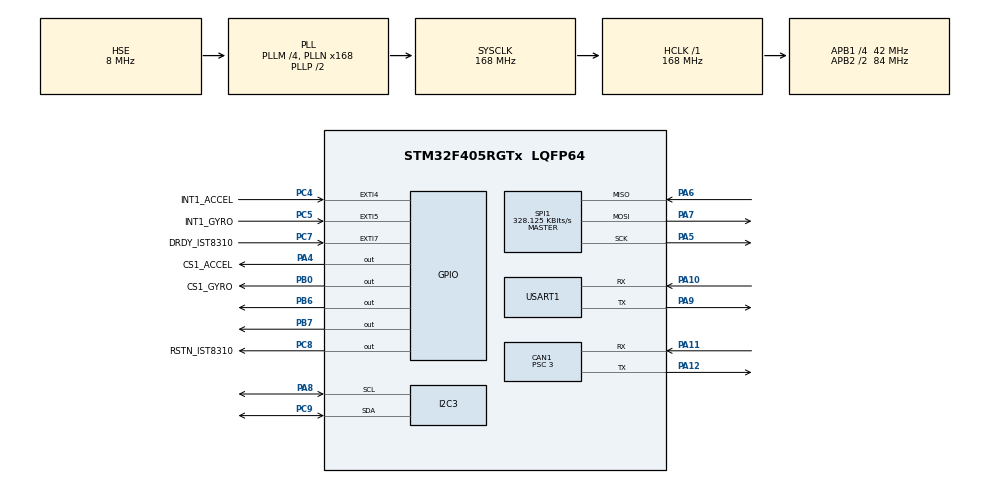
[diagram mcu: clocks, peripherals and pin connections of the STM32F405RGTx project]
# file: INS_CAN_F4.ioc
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CAN1.BS1=CAN_BS1_10TQ
CAN1.BS2=CAN_BS2_3TQ
CAN1.CalculateBaudRate=1000000
CAN1.CalculateTimeBit=1000
CAN1.CalculateTimeQuantum=71.42857142857143
CAN1.Prescaler=3
Dma.Request0=USART1_TX
Dma.Request1=SPI1_RX
Dma.Request2=SPI1_TX
Dma.SPI1_RX.1.Direction=DMA_PERIPH_TO_MEMORY
Dma.SPI1_RX.1.FIFOMode=DMA_FIFOMODE_DISABLE
Dma.SPI1_RX.1.Instance=DMA2_Stream2
Dma.SPI1_RX.1.MemDataAlignment=DMA_MDATAALIGN_BYTE
Dma.SPI1_RX.1.MemInc=DMA_MINC_ENABLE
Dma.SPI1_RX.1.Mode=DMA_NORMAL
Dma.SPI1_RX.1.PeriphDataAlignment=DMA_PDATAALIGN_BYTE
Dma.SPI1_RX.1.PeriphInc=DMA_PINC_DISABLE
Dma.SPI1_RX.1.Priority=DMA_PRIORITY_VERY_HIGH
Dma.SPI1_TX.2.Direction=DMA_MEMORY_TO_PERIPH
Dma.SPI1_TX.2.FIFOMode=DMA_FIFOMODE_DISABLE
Dma.SPI1_TX.2.Instance=DMA2_Stream3
Dma.SPI1_TX.2.MemDataAlignment=DMA_MDATAALIGN_BYTE
Dma.SPI1_TX.2.MemInc=DMA_MINC_ENABLE
Dma.SPI1_TX.2.Mode=DMA_NORMAL
Dma.SPI1_TX.2.PeriphDataAlignment=DMA_PDATAALIGN_BYTE
Dma.SPI1_TX.2.PeriphInc=DMA_PINC_DISABLE
Dma.SPI1_TX.2.Priority=DMA_PRIORITY_HIGH
Dma.USART1_TX.0.Direction=DMA_MEMORY_TO_PERIPH
Dma.USART1_TX.0.FIFOMode=DMA_FIFOMODE_DISABLE
Dma.USART1_TX.0.Instance=DMA2_Stream7
Dma.USART1_TX.0.MemDataAlignment=DMA_MDATAALIGN_BYTE
Dma.USART1_TX.0.MemInc=DMA_MINC_ENABLE
Dma.USART1_TX.0.Mode=DMA_NORMAL
Dma.USART1_TX.0.PeriphDataAlignment=DMA_PDATAALIGN_BYTE
Dma.USART1_TX.0.PeriphInc=DMA_PINC_DISABLE
Dma.USART1_TX.0.Priority=DMA_PRIORITY_VERY_HIGH
FREERTOS.INCLUDE_eTaskGetState=1
FREERTOS.INCLUDE_pcTaskGetTaskName=1
FREERTOS.INCLUDE_uxTaskGetStackHighWaterMark=1
FREERTOS.INCLUDE_vTaskCleanUpResources=1
FREERTOS.INCLUDE_vTaskDelayUntil=1
FREERTOS.INCLUDE_xEventGroupSetBitFromISR=1
FREERTOS.INCLUDE_xQueueGetMutexHolder=1
FREERTOS.INCLUDE_xSemaphoreGetMutexHolder=1
FREERTOS.INCLUDE_xTaskAbortDelay=1
FREERTOS.INCLUDE_xTaskGetCurrentTaskHandle=1
FREERTOS.INCLUDE_xTaskGetHandle=1
FREERTOS.INCLUDE_xTimerPendFunctionCall=1
FREERTOS.Tasks01=defaultTask,0,128,StartDefaultTask,As weak,NULL,Dynamic,NULL,NULL;sendTask,-3,256,SendTask,As weak,NULL,Dynamic,NULL,NULL
FREERTOS.configTOTAL_HEAP_SIZE=24576
FREERTOS.configUSE_TIMERS=1
I2C3.I2C_Mode=I2C_Fast
Mcu.Family=STM32F4
Mcu.Name=STM32F405RGTx
Mcu.Package=LQFP64
NVIC.CAN1_RX0_IRQn=true\:5\:0\:true\:false\:true\:true\:true\:true\:true
NVIC.CAN1_RX1_IRQn=true\:5\:0\:true\:false\:true\:true\:true\:true\:true
NVIC.DMA2_Stream2_IRQn=true\:5\:0\:true\:false\:false\:true\:false\:true\:true
NVIC.DMA2_Stream3_IRQn=true\:5\:0\:true\:false\:false\:true\:false\:true\:true
NVIC.DMA2_Stream7_IRQn=true\:5\:0\:true\:false\:true\:true\:false\:true\:true
NVIC.EXTI4_IRQn=true\:5\:0\:true\:false\:true\:true\:true\:true\:true
NVIC.EXTI9_5_IRQn=true\:5\:0\:true\:false\:true\:true\:true\:true\:true
NVIC.PriorityGroup=NVIC_PRIORITYGROUP_4
NVIC.TIM2_IRQn=true\:3\:0\:true\:false\:true\:false\:false\:true\:true
NVIC.TimeBase=TIM2_IRQn
NVIC.TimeBaseIP=TIM2
NVIC.USART1_IRQn=true\:5\:0\:false\:false\:true\:true\:true\:true\:true
PA10.Mode=Asynchronous
PA10.Signal=USART1_RX
PA11.GPIO_PuPd=GPIO_NOPULL
PA11.Mode=CAN_Activate
PA11.Signal=CAN1_RX
PA12.Mode=CAN_Activate
PA12.Signal=CAN1_TX
PA13.Mode=Serial_Wire
PA13.Signal=SYS_JTMS-SWDIO
PA14.Mode=Serial_Wire
PA14.Signal=SYS_JTCK-SWCLK
PA4.GPIO_Label=CS1_ACCEL
PA4.GPIO_PuPd=GPIO_PULLUP
PA4.GPIO_Speed=GPIO_SPEED_FREQ_HIGH
PA4.PinState=GPIO_PIN_SET
PA4.Signal=GPIO_Output
PA5.GPIO_PuPd=GPIO_PULLUP
PA5.Mode=Full_Duplex_Master
PA5.Signal=SPI1_SCK
PA6.GPIO_PuPd=GPIO_PULLUP
PA6.Mode=Full_Duplex_Master
PA6.Signal=SPI1_MISO
PA7.GPIO_PuPd=GPIO_PULLUP
PA7.Mode=Full_Duplex_Master
PA7.Signal=SPI1_MOSI
PA8.GPIO_Pu=GPIO_PULLUP
PA8.Mode=I2C
PA8.Signal=I2C3_SCL
PA9.Mode=Asynchronous
PA9.Signal=USART1_TX
PB0.GPIO_Label=CS1_GYRO
PB0.GPIO_PuPd=GPIO_PULLUP
PB0.GPIO_Speed=GPIO_SPEED_FREQ_HIGH
PB0.PinState=GPIO_PIN_SET
PB0.Signal=GPIO_Output
PB6.GPIO_ModeDefaultOutputPP=GPIO_MODE_OUTPUT_PP
PB6.GPIO_PuPd=GPIO_PULLUP
PB6.GPIO_Speed=GPIO_SPEED_FREQ_VERY_HIGH
PB6.PinState=GPIO_PIN_SET
PB6.Signal=GPIO_Output
PB7.GPIO_ModeDefaultOutputPP=GPIO_MODE_OUTPUT_OD
PB7.GPIO_PuPd=GPIO_PULLUP
PB7.GPIO_Speed=GPIO_SPEED_FREQ_VERY_HIGH
PB7.PinState=GPIO_PIN_SET
PB7.Signal=GPIO_Output
PC4.GPIO_Label=INT1_ACCEL
PC4.GPIO_ModeDefaultEXTI=GPIO_MODE_IT_FALLING
PC4.GPIO_PuPd=GPIO_PULLUP
PC4.Signal=GPXTI4
PC5.GPIO_Label=INT1_GYRO
PC5.GPIO_ModeDefaultEXTI=GPIO_MODE_IT_FALLING
PC5.GPIO_PuPd=GPIO_PULLUP
PC5.Signal=GPXTI5
PC7.GPIO_Label=DRDY_IST8310
PC7.GPIO_ModeDefaultEXTI=GPIO_MODE_IT_FALLING
PC7.GPIO_PuPd=GPIO_PULLUP
PC7.Signal=GPXTI7
PC8.GPIO_Label=RSTN_IST8310
PC8.GPIO_PuPd=GPIO_PULLUP
PC8.GPIO_Speed=GPIO_SPEED_FREQ_MEDIUM
PC8.PinState=GPIO_PIN_SET
PC8.Signal=GPIO_Output
PC9.GPIO_Pu=GPIO_PULLUP
PC9.Mode=I2C
PC9.Signal=I2C3_SDA
PH0-OSC_IN.Mode=HSE-External-Oscillator
PH0-OSC_IN.Signal=RCC_OSC_IN
PH1-OSC_OUT.Mode=HSE-External-Oscillator
PH1-OSC_OUT.Signal=RCC_OSC_OUT
ProjectManager.HeapSize=0x2000
ProjectManager.StackSize=0x4000
ProjectManager.TargetToolchain=MDK-ARM V5
RCC.48MHZClocksFreq_Value=84000000
RCC.AHBFreq_Value=168000000
RCC.APB1CLKDivider=RCC_HCLK_DIV4
RCC.APB1Freq_Value=42000000
RCC.APB1TimFreq_Value=84000000
RCC.APB2CLKDivider=RCC_HCLK_DIV2
RCC.APB2Freq_Value=84000000
RCC.APB2TimFreq_Value=168000000
RCC.CortexFreq_Value=168000000
RCC.HCLKFreq_Value=168000000
RCC.HSE_VALUE=8000000
RCC.HSI_VALUE=16000000
RCC.LSE_VALUE=32768
RCC.PLLM=4
RCC.PLLN=168
RCC.PLLSourceVirtual=RCC_PLLSOURCE_HSE
RCC.SYSCLKFreq_VALUE=168000000
RCC.SYSCLKSource=RCC_SYSCLKSOURCE_PLLCLK
RCC.VCOOutputFreq_Value=336000000
SPI1.BaudRatePrescaler=SPI_BAUDRATEPRESCALER_256
SPI1.CLKPhase=SPI_PHASE_2EDGE
SPI1.CLKPolarity=SPI_POLARITY_HIGH
SPI1.CalculateBaudRate=328.125 KBits/s
SPI1.Direction=SPI_DIRECTION_2LINES
SPI1.Mode=SPI_MODE_MASTER
SPI1.VirtualType=VM_MASTER
USART1.VirtualMode=VM_ASYNC
VP_FREERTOS_VS_CMSIS_V1.Mode=CMSIS_V1
VP_SYS_VS_tim2.Mode=TIM2
board=custom

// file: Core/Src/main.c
/* USER CODE BEGIN Header */
/**
  ******************************************************************************
  * @file           : main.c
  * @brief          : Main program body
  ******************************************************************************
  * @attention
  *
  * Copyright (c) 2023 STMicroelectronics.
  * All rights reserved.
  *
  * This software is licensed under terms that can be found in the LICENSE file
  * in the root directory of this software component.
  * If no LICENSE file comes with this software, it is provided AS-IS.
  *
  ******************************************************************************
  */
/* USER CODE END Header */
#include "main.h"
#include "cmsis_os.h"
#include "can.h"
#include "dma.h"
#include "i2c.h"
#include "spi.h"
#include "usart.h"
#include "gpio.h"

void SystemClock_Config(void);
void MX_FREERTOS_Init(void);

int main(void)
{

  /* MCU Configuration--------------------------------------------------------*/

  /* Reset of all peripherals, Initializes the Flash interface and the Systick. */
  HAL_Init();

  /* Configure the system clock */
  SystemClock_Config();

  /* Initialize all configured peripherals */
  MX_GPIO_Init();
  MX_DMA_Init();
  MX_CAN1_Init();
  MX_I2C3_Init();
  MX_SPI1_Init();
  MX_USART1_UART_Init();

  /* Call init function for freertos objects (in freertos.c) */
  MX_FREERTOS_Init();

  /* Start scheduler */
  osKernelStart();
  /* We should never get here as control is now taken by the scheduler */
  /* Infinite loop */
  while (1)
  {

  }
}

void SystemClock_Config(void)
{
  RCC_OscInitTypeDef RCC_OscInitStruct = {0};
  RCC_ClkInitTypeDef RCC_ClkInitStruct = {0};

  /** Configure the main internal regulator output voltage
  */
  __HAL_RCC_PWR_CLK_ENABLE();
  __HAL_PWR_VOLTAGESCALING_CONFIG(PWR_REGULATOR_VOLTAGE_SCALE1);

  /** Initializes the RCC Oscillators according to the specified parameters
  * in the RCC_OscInitTypeDef structure.
  */
  RCC_OscInitStruct.OscillatorType = RCC_OSCILLATORTYPE_HSE;
  RCC_OscInitStruct.HSEState = RCC_HSE_ON;
  RCC_OscInitStruct.PLL.PLLState = RCC_PLL_ON;
  RCC_OscInitStruct.PLL.PLLSource = RCC_PLLSOURCE_HSE;
  RCC_OscInitStruct.PLL.PLLM = 4;
  RCC_OscInitStruct.PLL.PLLN = 168;
  RCC_OscInitStruct.PLL.PLLP = RCC_PLLP_DIV2;
  RCC_OscInitStruct.PLL.PLLQ = 4;
  if (HAL_RCC_OscConfig(&RCC_OscInitStruct) != HAL_OK)
  {
    Error_Handler();
  }

  /** Initializes the CPU, AHB and APB buses clocks
  */
  RCC_ClkInitStruct.ClockType = RCC_CLOCKTYPE_HCLK|RCC_CLOCKTYPE_SYSCLK
                              |RCC_CLOCKTYPE_PCLK1|RCC_CLOCKTYPE_PCLK2;
  RCC_ClkInitStruct.SYSCLKSource = RCC_SYSCLKSOURCE_PLLCLK;
  RCC_ClkInitStruct.AHBCLKDivider = RCC_SYSCLK_DIV1;
  RCC_ClkInitStruct.APB1CLKDivider = RCC_HCLK_DIV4;
  RCC_ClkInitStruct.APB2CLKDivider = RCC_HCLK_DIV2;

  if (HAL_RCC_ClockConfig(&RCC_ClkInitStruct, FLASH_LATENCY_5) != HAL_OK)
  {
    Error_Handler();
  }
}

void HAL_TIM_PeriodElapsedCallback(TIM_HandleTypeDef *htim)
{
  if (htim->Instance == TIM2) {
    HAL_IncTick();
  }
}

void Error_Handler(void)
{
  __disable_irq();
  while (1)
  {
  }
}

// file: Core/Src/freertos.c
/* USER CODE BEGIN Header */
/**
  ******************************************************************************
  * File Name          : freertos.c
  * Description        : Code for freertos applications
  ******************************************************************************
  * @attention
  *
  * Copyright (c) 2023 STMicroelectronics.
  * All rights reserved.
  *
  * This software is licensed under terms that can be found in the LICENSE file
  * in the root directory of this software component.
  * If no LICENSE file comes with this software, it is provided AS-IS.
  *
  ******************************************************************************
  */
/* USER CODE END Header */

#include "FreeRTOS.h"
#include "task.h"
#include "main.h"
#include "cmsis_os.h"

/* USER CODE BEGIN Includes */
#include "INS_task.h"
/* USER CODE END Includes */

/* USER CODE BEGIN PTD */
osThreadId imuTaskHandle;
/* USER CODE END PTD */

osThreadId defaultTaskHandle;
osThreadId sendTaskHandle;

void StartDefaultTask(void const * argument);
void SendTask(void const * argument);

void MX_FREERTOS_Init(void); /* (MISRA C 2004 rule 8.1) */

/* GetIdleTaskMemory prototype (linked to static allocation support) */
void vApplicationGetIdleTaskMemory( StaticTask_t **ppxIdleTaskTCBBuffer, StackType_t **ppxIdleTaskStackBuffer, uint32_t *pulIdleTaskStackSize );

/* GetTimerTaskMemory prototype (linked to static allocation support) */
void vApplicationGetTimerTaskMemory( StaticTask_t **ppxTimerTaskTCBBuffer, StackType_t **ppxTimerTaskStackBuffer, uint32_t *pulTimerTaskStackSize );

/* USER CODE BEGIN GET_IDLE_TASK_MEMORY */
static StaticTask_t xIdleTaskTCBBuffer;
static StackType_t xIdleStack[configMINIMAL_STACK_SIZE];

void vApplicationGetIdleTaskMemory( StaticTask_t **ppxIdleTaskTCBBuffer, StackType_t **ppxIdleTaskStackBuffer, uint32_t *pulIdleTaskStackSize )
{
  *ppxIdleTaskTCBBuffer = &xIdleTaskTCBBuffer;
  *ppxIdleTaskStackBuffer = &xIdleStack[0];
  *pulIdleTaskStackSize = configMINIMAL_STACK_SIZE;
  /* place for user code */
}
/* USER CODE END GET_IDLE_TASK_MEMORY */

/* USER CODE BEGIN GET_TIMER_TASK_MEMORY */
static StaticTask_t xTimerTaskTCBBuffer;
static StackType_t xTimerStack[configTIMER_TASK_STACK_DEPTH];

void vApplicationGetTimerTaskMemory( StaticTask_t **ppxTimerTaskTCBBuffer, StackType_t **ppxTimerTaskStackBuffer, uint32_t *pulTimerTaskStackSize )
{
  *ppxTimerTaskTCBBuffer = &xTimerTaskTCBBuffer;
  *ppxTimerTaskStackBuffer = &xTimerStack[0];
  *pulTimerTaskStackSize = configTIMER_TASK_STACK_DEPTH;
  /* place for user code */
}
/* USER CODE END GET_TIMER_TASK_MEMORY */

void MX_FREERTOS_Init(void) {

  /* Create the thread(s) */
  /* definition and creation of defaultTask */
  osThreadDef(defaultTask, StartDefaultTask, osPriorityNormal, 0, 128);
  defaultTaskHandle = osThreadCreate(osThread(defaultTask), NULL);

  /* definition and creation of sendTask */
  osThreadDef(sendTask, SendTask, osPriorityIdle, 0, 256);
  sendTaskHandle = osThreadCreate(osThread(sendTask), NULL);

  /* USER CODE BEGIN RTOS_THREADS */
  /* add threads, ... */
  osThreadDef(imuTask, INS_task, osPriorityRealtime, 0, 1024);
    imuTaskHandle = osThreadCreate(osThread(imuTask), NULL);
  /* USER CODE END RTOS_THREADS */

}

__weak void StartDefaultTask(void const * argument)
{
  for(;;)
  {
    osDelay(1);
  }
}

__weak void SendTask(void const * argument)
{
  for(;;)
  {
    osDelay(1);
  }
}
